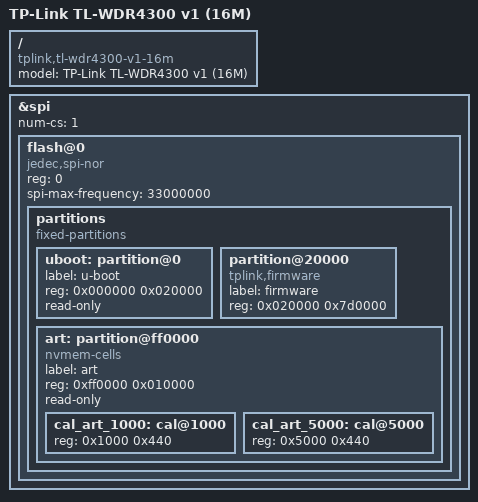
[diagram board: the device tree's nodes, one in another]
// SPDX-License-Identifier: GPL-2.0-or-later OR MIT

#include "ar9344_tplink_tl-wdr4300.dtsi"

/ {
	model = "TP-Link TL-WDR4300 v1 (16M)";
	compatible = "tplink,tl-wdr4300-v1-16m", "qca,ar9344";
};

&spi {
	num-cs = <1>;
        status = "okay";

        flash@0 {
                compatible = "jedec,spi-nor";
                reg = <0>;
                spi-max-frequency = <33000000>;

                partitions {
                        compatible = "fixed-partitions";
                        #address-cells = <1>;
                        #size-cells = <1>;

                        uboot: partition@0 {
                                label = "u-boot";
                                reg = <0x000000 0x020000>;
                                read-only;
                        };

                        partition@20000 {
                                compatible = "tplink,firmware";
                                label = "firmware";
                                reg = <0x020000 0x7d0000>;
                        };

			/delete-node/ partition@7f0000;
                        art: partition@ff0000 {
                                label = "art";
                                reg = <0xff0000 0x010000>;
                                read-only;
                        };
                };
        };
};

&art {  
        compatible = "nvmem-cells";
        #address-cells = <1>;
        #size-cells = <1>;

        cal_art_1000: cal@1000 {
                reg = <0x1000 0x440>;
        };

        cal_art_5000: cal@5000 {
                reg = <0x5000 0x440>;
        };
};


